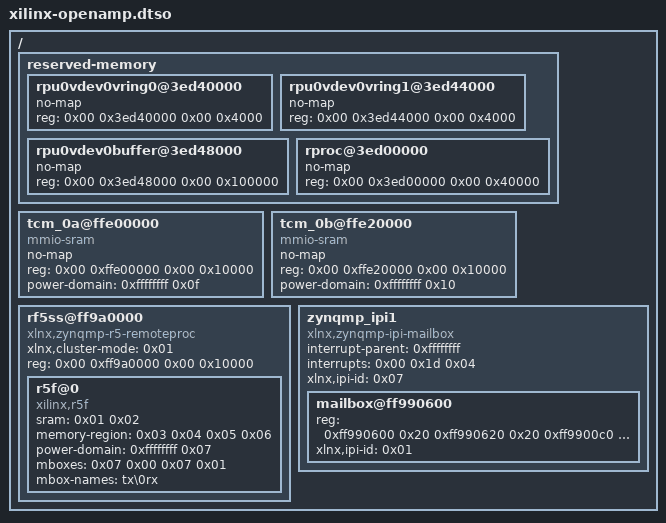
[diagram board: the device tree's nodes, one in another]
/dts-v1/;

/ {

	fragment@0 {
		target-path = "/";

		__overlay__ {

			reserved-memory {
				#address-cells = <0x02>;
				#size-cells = <0x02>;
				ranges;

				rpu0vdev0vring0@3ed40000 {
					no-map;
					reg = <0x00 0x3ed40000 0x00 0x4000>;
					phandle = <0x05>;
				};

				rpu0vdev0vring1@3ed44000 {
					no-map;
					reg = <0x00 0x3ed44000 0x00 0x4000>;
					phandle = <0x06>;
				};

				rpu0vdev0buffer@3ed48000 {
					no-map;
					reg = <0x00 0x3ed48000 0x00 0x100000>;
					phandle = <0x04>;
				};

				rproc@3ed00000 {
					no-map;
					reg = <0x00 0x3ed00000 0x00 0x40000>;
					phandle = <0x03>;
				};
			};

			tcm_0a@ffe00000 {
				no-map;
				reg = <0x00 0xffe00000 0x00 0x10000>;
				status = "okay";
				compatible = "mmio-sram";
				power-domain = <0xffffffff 0x0f>;
				phandle = <0x01>;
			};

			tcm_0b@ffe20000 {
				no-map;
				reg = <0x00 0xffe20000 0x00 0x10000>;
				status = "okay";
				compatible = "mmio-sram";
				power-domain = <0xffffffff 0x10>;
				phandle = <0x02>;
			};

			rf5ss@ff9a0000 {
				compatible = "xlnx,zynqmp-r5-remoteproc";
				xlnx,cluster-mode = <0x01>;
				ranges;
				reg = <0x00 0xff9a0000 0x00 0x10000>;
				#address-cells = <0x02>;
				#size-cells = <0x02>;

				r5f@0 {
					compatible = "xilinx,r5f";
					#address-cells = <0x02>;
					#size-cells = <0x02>;
					ranges;
					sram = <0x01 0x02>;
					memory-region = <0x03 0x04 0x05 0x06>;
					power-domain = <0xffffffff 0x07>;
					mboxes = <0x07 0x00 0x07 0x01>;
					mbox-names = "tx\0rx";
					phandle = <0x08>;
				};
			};

			zynqmp_ipi1 {
				compatible = "xlnx,zynqmp-ipi-mailbox";
				interrupt-parent = <0xffffffff>;
				interrupts = <0x00 0x1d 0x04>;
				xlnx,ipi-id = <0x07>;
				#address-cells = <0x01>;
				#size-cells = <0x01>;
				ranges;

				mailbox@ff990600 {
					reg = <0xff990600 0x20 0xff990620 0x20 0xff9900c0 0x20 0xff9900e0 0x20>;
					reg-names = "local_request_region\0local_response_region\0remote_request_region\0remote_response_region";
					#mbox-cells = <0x01>;
					xlnx,ipi-id = <0x01>;
					phandle = <0x07>;
				};
			};
		};
	};

	__symbols__ {
		rpu0vdev0vring0 = "/fragment@0/__overlay__/reserved-memory/rpu0vdev0vring0@3ed40000";
		rpu0vdev0vring1 = "/fragment@0/__overlay__/reserved-memory/rpu0vdev0vring1@3ed44000";
		rpu0vdev0buffer = "/fragment@0/__overlay__/reserved-memory/rpu0vdev0buffer@3ed48000";
		rproc_0_reserved = "/fragment@0/__overlay__/reserved-memory/rproc@3ed00000";
		tcm_0a = "/fragment@0/__overlay__/tcm_0a@ffe00000";
		tcm_0b = "/fragment@0/__overlay__/tcm_0b@ffe20000";
		r5f_0 = "/fragment@0/__overlay__/rf5ss@ff9a0000/r5f@0";
		ipi_mailbox_rpu0 = "/fragment@0/__overlay__/zynqmp_ipi1/mailbox@ff990600";
	};

	__fixups__ {
		zynqmp_firmware = "/fragment@0/__overlay__/tcm_0a@ffe00000:power-domain:0\0/fragment@0/__overlay__/tcm_0b@ffe20000:power-domain:0\0/fragment@0/__overlay__/rf5ss@ff9a0000/r5f@0:power-domain:0";
		gic = "/fragment@0/__overlay__/zynqmp_ipi1:interrupt-parent:0";
	};

	__local_fixups__ {

		fragment@0 {

			__overlay__ {

				rf5ss@ff9a0000 {

					r5f@0 {
						sram = <0x00 0x04>;
						memory-region = <0x00 0x04 0x08 0x0c>;
						mboxes = <0x00 0x08>;
					};
				};
			};
		};
	};
};
